# N32G030 register map
Vendor: Nationstech Ltd.; File version: 1.0
Registers are 32-bit, read-write, reset 0x0 unless marked. A register's access mark holds for its fields unless they carry their own. Offsets are from the block's base; [hi:lo] are bit positions; {n}, {i} and the like mark numbered series; 'fields as' and 'values as' point back to an identical list.

## RCC — Reset and clock control
Base 0x40021000
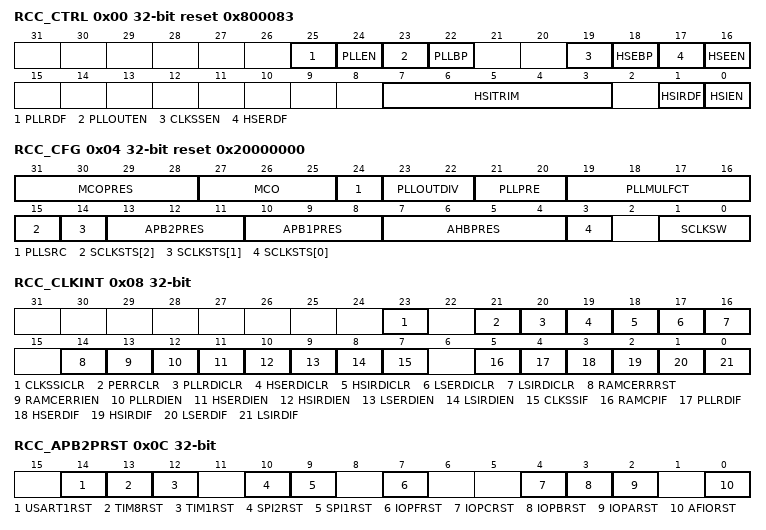
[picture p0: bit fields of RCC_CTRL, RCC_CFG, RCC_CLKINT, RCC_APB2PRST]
0x00 RCC_CTRL reset 0x800083 (reset mask 0x3CB00FB)
  [25] PLLRDF, [24] PLLEN, [23] PLLOUTEN, [22] PLLBP, [19] CLKSSEN, [18] HSEBP, [17] HSERDF, [16] HSEEN, [7:3] HSITRIM, [1] HSIRDF, [0] HSIEN
0x04 RCC_CFG reset 0x20000000
  [31:28] MCOPRES, [27:25] MCO, [24] PLLSRC, [23:22] PLLOUTDIV, [21:20] PLLPRE, [19:16] PLLMULFCT, [15] SCLKSTS[2], [14] SCLKSTS[1], [13:11] APB2PRES, [10:8] APB1PRES, [7:4] AHBPRES, [3] SCLKSTS[0], [1:0] SCLKSW
0x08 RCC_CLKINT
  [23] CLKSSICLR, [21] PERRCLR, [20] PLLRDICLR, [19] HSERDICLR, [18] HSIRDICLR, [17] LSERDICLR, [16] LSIRDICLR, [14] RAMCERRRST, [13] RAMCERRIEN, [12] PLLRDIEN, [11] HSERDIEN, [10] HSIRDIEN, [9] LSERDIEN, [8] LSIRDIEN, [7] CLKSSIF, [5] RAMCPIF, [4] PLLRDIF, [3] HSERDIF, [2] HSIRDIF, [1] LSERDIF, [0] LSIRDIF
0x0C RCC_APB2PRST
  [14] USART1RST, [13] TIM8RST, [12] TIM1RST, [10] SPI2RST, [9] SPI1RST, [7] IOPFRST, [4] IOPCRST, [3] IOPBRST, [2] IOPARST, [0] AFIORST
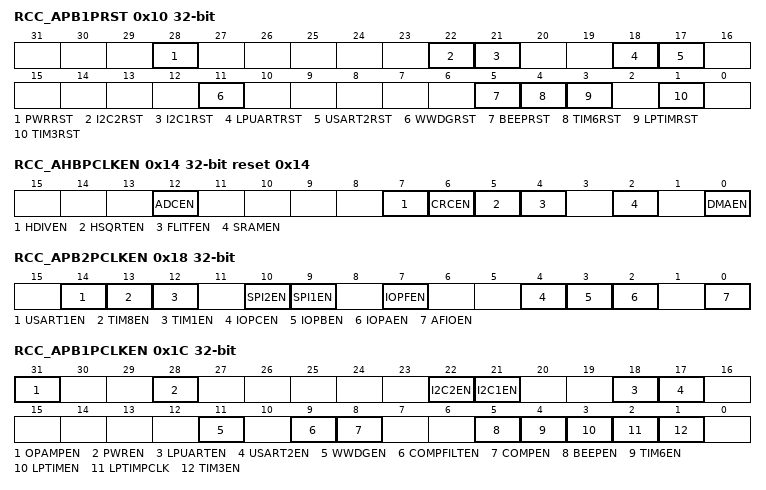
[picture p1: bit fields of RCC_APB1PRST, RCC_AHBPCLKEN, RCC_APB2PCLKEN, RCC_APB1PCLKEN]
0x10 RCC_APB1PRST
  [28] PWRRST, [22] I2C2RST, [21] I2C1RST, [18] LPUARTRST, [17] USART2RST, [11] WWDGRST, [5] BEEPRST, [4] TIM6RST, [3] LPTIMRST, [1] TIM3RST
0x14 RCC_AHBPCLKEN reset 0x14
  [12] ADCEN, [7] HDIVEN, [6] CRCEN, [5] HSQRTEN, [4] FLITFEN, [2] SRAMEN, [0] DMAEN
0x18 RCC_APB2PCLKEN
  [14] USART1EN, [13] TIM8EN, [12] TIM1EN, [10] SPI2EN, [9] SPI1EN, [7] IOPFEN, [4] IOPCEN, [3] IOPBEN, [2] IOPAEN, [0] AFIOEN
0x1C RCC_APB1PCLKEN
  [31] OPAMPEN, [28] PWREN, [22] I2C2EN, [21] I2C1EN, [18] LPUARTEN, [17] USART2EN, [11] WWDGEN, [9] COMPFILTEN, [8] COMPEN, [5] BEEPEN, [4] TIM6EN, [3] LPTIMEN, [2] LPTIMPCLK, [1] TIM3EN
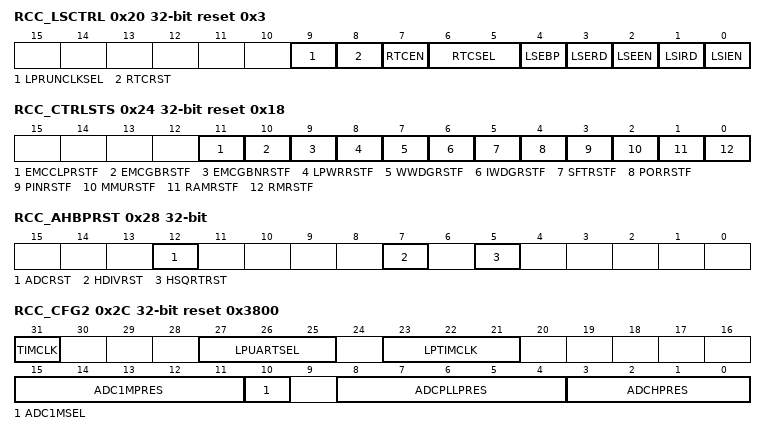
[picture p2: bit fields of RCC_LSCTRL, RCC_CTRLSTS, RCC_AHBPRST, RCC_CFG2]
0x20 RCC_LSCTRL reset 0x3
  [9] LPRUNCLKSEL, [8] RTCRST, [7] RTCEN, [6:5] RTCSEL, [4] LSEBP, [3] LSERD, [2] LSEEN, [1] LSIRD, [0] LSIEN
0x24 RCC_CTRLSTS reset 0x18
  [11] EMCCLPRSTF, [10] EMCGBRSTF, [9] EMCGBNRSTF, [8] LPWRRSTF, [7] WWDGRSTF, [6] IWDGRSTF, [5] SFTRSTF, [4] PORRSTF, [3] PINRSTF, [2] MMURSTF, [1] RAMRSTF, [0] RMRSTF
0x28 RCC_AHBPRST
  [12] ADCRST, [7] HDIVRST, [5] HSQRTRST
0x2C RCC_CFG2 reset 0x3800
  [31] TIMCLK, [27:25] LPUARTSEL, [23:21] LPTIMCLK, [15:11] ADC1MPRES, [10] ADC1MSEL, [8:4] ADCPLLPRES, [3:0] ADCHPRES
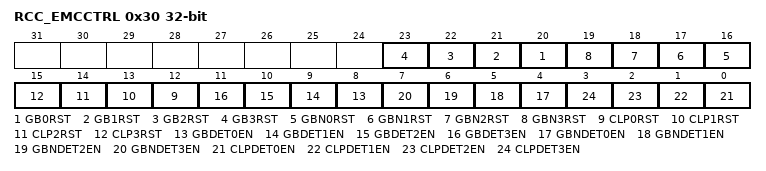
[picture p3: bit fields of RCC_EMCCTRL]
0x30 RCC_EMCCTRL
  [n+20] GB{n}RST (n=0..3), [n+16] GBN{n}RST (n=0..3), [n+12] CLP{n}RST (n=0..3), [n+8] GBDET{n}EN (n=0..3), [n+4] GBNDET{n}EN (n=0..3), [n] CLPDET{n}EN (n=0..3)

## RTC — Real time clock
Base 0x40002800
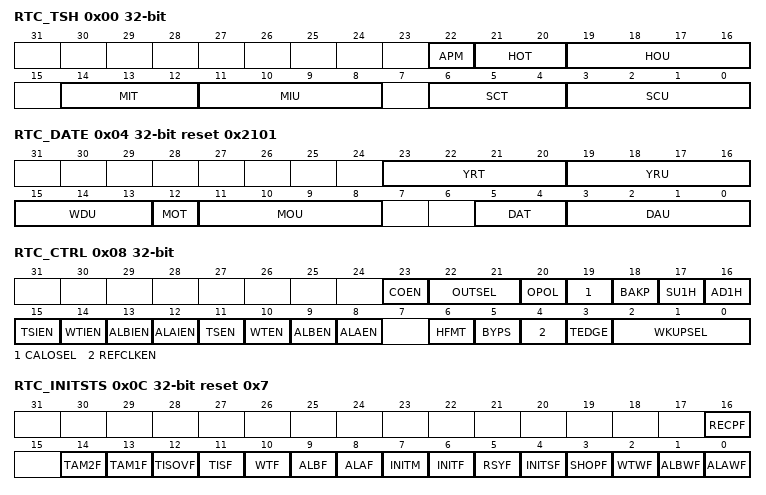
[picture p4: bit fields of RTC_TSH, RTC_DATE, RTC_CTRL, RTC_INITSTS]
0x00 RTC_TSH
  [22] APM, [21:20] HOT, [19:16] HOU, [14:12] MIT, [11:8] MIU, [6:4] SCT, [3:0] SCU
0x04 RTC_DATE reset 0x2101
  [23:20] YRT, [19:16] YRU, [15:13] WDU, [12] MOT, [11:8] MOU, [5:4] DAT, [3:0] DAU
0x08 RTC_CTRL
  [23] COEN, [22:21] OUTSEL, [20] OPOL, [19] CALOSEL, [18] BAKP, [17] SU1H, [16] AD1H, [15] TSIEN, [14] WTIEN, [13] ALBIEN, [12] ALAIEN, [11] TSEN, [10] WTEN, [9] ALBEN, [8] ALAEN, [6] HFMT, [5] BYPS, [4] REFCLKEN, [3] TEDGE, [2:0] WKUPSEL
0x0C RTC_INITSTS reset 0x7
  [16] RECPF, [14] TAM2F, [13] TAM1F, [12] TISOVF, [11] TISF, [10] WTF, [9] ALBF, [8] ALAF, [7] INITM, [6] INITF, [5] RSYF, [4] INITSF, [3] SHOPF, [2] WTWF, [1] ALBWF, [0] ALAWF
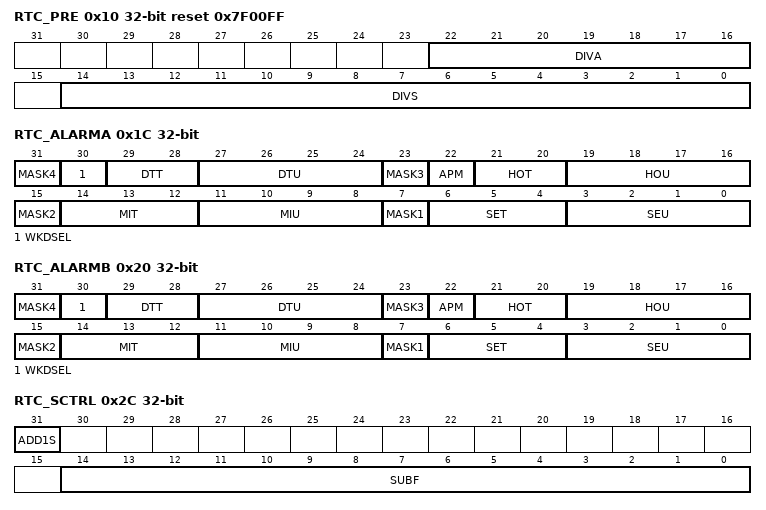
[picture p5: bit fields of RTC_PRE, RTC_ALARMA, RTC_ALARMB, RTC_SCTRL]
0x10 RTC_PRE reset 0x7F00FF
  [22:16] DIVA, [14:0] DIVS
0x14 RTC_WKUPT reset 0xFFFF
  [15:0] WKUPT
0x1C RTC_ALARMA
  [8n-1] MASK{n} (n=1..4), [30] WKDSEL, [29:28] DTT, [27:24] DTU, [22] APM, [21:20] HOT, [19:16] HOU, [14:12] MIT, [11:8] MIU, [6:4] SET, [3:0] SEU
0x20 RTC_ALARMB
  fields as RTC_ALARMA
0x24 RTC_WRP
  [7:0] PKEY
0x28 RTC_SUBS
  [15:0] SS
0x2C RTC_SCTRL
  [31] ADD1S
  [14:0] SUBF — SUB1S
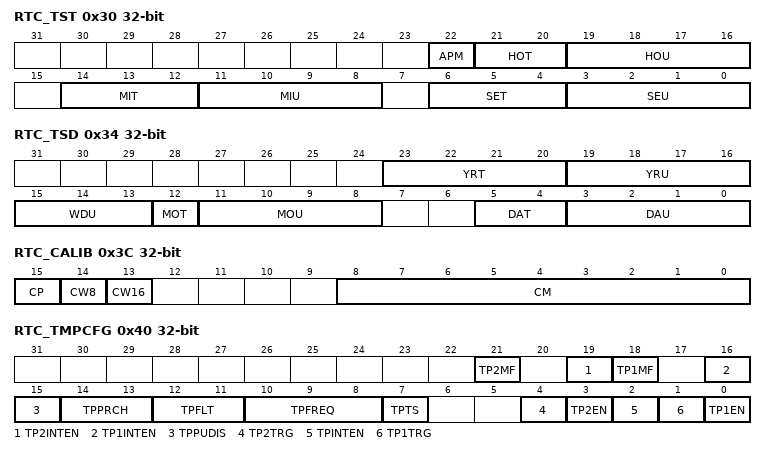
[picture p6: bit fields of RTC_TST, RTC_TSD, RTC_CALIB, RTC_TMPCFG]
0x30 RTC_TST (reset mask 0x7F)
  [22] APM, [21:20] HOT, [19:16] HOU, [14:12] MIT, [11:8] MIU, [6:4] SET, [3:0] SEU
0x34 RTC_TSD
  fields as RTC_DATE
0x38 RTC_TSSS
  [15:0] SSE
0x3C RTC_CALIB (reset mask 0xFF)
  [15] CP, [14] CW8, [13] CW16, [8:0] CM
0x40 RTC_TMPCFG
  [21] TP2MF, [19] TP2INTEN, [18] TP1MF, [16] TP1INTEN, [15] TPPUDIS, [14:13] TPPRCH, [12:11] TPFLT, [10:8] TPFREQ, [7] TPTS, [4] TP2TRG, [3] TP2EN, [2] TPINTEN, [1] TP1TRG, [0] TP1EN
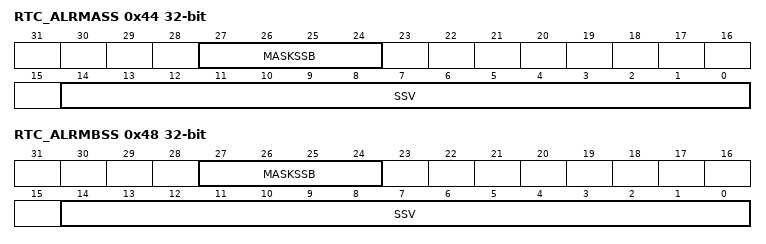
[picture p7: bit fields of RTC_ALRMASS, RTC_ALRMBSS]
0x44 RTC_ALRMASS
  [27:24] MASKSSB, [14:0] SSV
0x48 RTC_ALRMBSS
  [27:24] MASKSSB, [14:0] SSV
